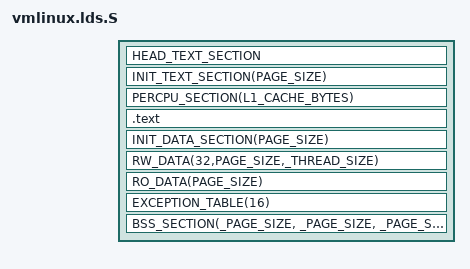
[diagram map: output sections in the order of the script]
FASTVC-BENCH-CORPUS:linux-main-100k-v1-e0bd41dc-8e12-4f1b-978d-a3645ae59da0
/* SPDX-License-Identifier: GPL-2.0-only */
/*
 * Linker script for Hexagon kernel
 *
 * Copyright (c) 2010-2014, The Linux Foundation. All rights reserved.
 */

#include <asm-generic/vmlinux.lds.h>
#include <asm/asm-offsets.h>	/*  Most of the kernel defines are here  */
#include <asm/mem-layout.h>	/*  except for page_offset  */
#include <asm/cache.h>		/*  and now we're pulling cache line size  */
#include <asm/thread_info.h>	/*  and we need THREAD_SIZE too */

OUTPUT_ARCH(hexagon)
ENTRY(stext)

jiffies = jiffies_64;

/*
See asm-generic/vmlinux.lds.h for expansion of some of these macros.
See asm-generic/sections.h for seemingly required labels.
*/

#define PAGE_SIZE _PAGE_SIZE

SECTIONS
{
	. = PAGE_OFFSET;

	__init_begin = .;
	HEAD_TEXT_SECTION
	INIT_TEXT_SECTION(PAGE_SIZE)
	PERCPU_SECTION(L1_CACHE_BYTES)
	__init_end = .;

        . = ALIGN(_PAGE_SIZE);
	_stext = .;
	.text : AT(ADDR(.text)) {
		_text = .;
		TEXT_TEXT
		SCHED_TEXT
/* bench 13066.0.0 e785c1c1b75f */
/* bench 13066.0.1 23a0d5a9bb0e */
/* bench 13066.0.2 2340bfca4a02 */
/* bench 13066.0.3 3d404ca67e1a */
/* bench 13066.0.4 2f441b98bff7 */
/* bench 13066.0.5 a82f1a43c477 */
/* bench 13066.0.6 f979dd497fc8 */
/* bench 13066.0.7 e7fbef10ead2 */
/* bench 13066.0.8 7d38056bb616 */
/* bench 13066.0.9 59d0dd8c3d1e */
/* bench 13066.0.10 acf58a04b5f2 */
/* bench 2166.2.0 fb56d293d5ac */
/* bench 2166.2.1 a3739d9f5caf */
/* bench 2166.2.2 e3186b31c8d6 */
/* bench 2166.2.3 24573002fec8 */
/* bench 2166.2.4 4c3aba47e08c */
/* bench 2166.2.5 2a247a4d15d6 */
/* bench 2166.2.6 3b156770ecb4 */
/* bench 2166.2.7 136025846610 */
/* bench 2166.2.8 3b0818d0a8ec */
/* bench 2166.2.9 d8089afff6b9 */
/* bench 2166.2.10 230e3ddd129f */
/* bench 2166.2.11 afeb1016a94d */
/* bench 2166.2.12 1d3924684f66 */
/* bench 2166.2.13 84303b67d3f9 */
/* bench 2166.2.14 8ad58f1e28fd */
/* bench 2166.2.15 e93b66369b48 */
		LOCK_TEXT
		KPROBES_TEXT
		*(.fixup)
	}
	_etext = .;

	INIT_DATA_SECTION(PAGE_SIZE)

	_sdata = .;
		RW_DATA(32,PAGE_SIZE,_THREAD_SIZE)
		RO_DATA(PAGE_SIZE)
	_edata = .;

	EXCEPTION_TABLE(16)

	BSS_SECTION(_PAGE_SIZE, _PAGE_SIZE, _PAGE_SIZE)

	_end = .;

	/DISCARD/ : {
		EXIT_TEXT
		EXIT_DATA
		EXIT_CALL
	}

	STABS_DEBUG
	DWARF_DEBUG
	ELF_DETAILS

}
/* bench 3865.1.0 206397c88eb0 */
/* bench 3865.1.1 a107d93ff7fe */
/* bench 3865.1.2 59b75078ad09 */
/* bench 3865.1.3 3a7607f4f4a6 */
/* bench 3865.1.4 bd55d867aa29 */
/* bench 3865.1.5 cdef42916c7f */
/* bench 3865.1.6 1745aa64c9cc */
/* bench 3865.1.7 b7533a19fb85 */
/* bench 3865.1.8 84873c3e9b49 */
/* bench 3865.1.9 825c752cbce5 */
